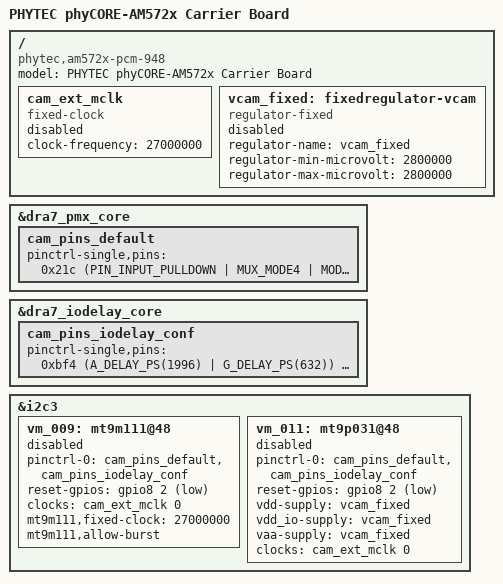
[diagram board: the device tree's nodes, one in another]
/*
 * Copyright (C) 2015 PHYTEC America, LLC - www.phytec.com
 *
 * This program is free software; you can redistribute it and/or modify
 * it under the terms of the GNU General Public License version 2 as
 * published by the Free Software Foundation.
 */

#include "am57xx-pcm-948-common.dtsi"

/ {
	model = "PHYTEC phyCORE-AM572x Carrier Board";
	compatible = "phytec,am572x-pcm-948", "phytec,am572x-phycore-som", "ti,am5728", "ti,dra742", "ti,dra74", "ti,dra7";

	/* For parallel camera interface at connector X23 */
	cam_ext_mclk: cam_ext_mclk {
		compatible = "fixed-clock";
		status = "disabled";

		#clock-cells = <0>;
		clock-frequency = <27000000>;
	};

	vcam_fixed: fixedregulator-vcam {
		compatible = "regulator-fixed";
		status = "disabled";

		regulator-name = "vcam_fixed";
		regulator-min-microvolt = <2800000>;
		regulator-max-microvolt = <2800000>;
	};
};

&dra7_pmx_core {
        cam_pins_default: cam_pins_default {
                pinctrl-single,pins = <
			0x21c (PIN_INPUT_PULLDOWN | MUX_MODE4 | MODE_SELECT)   /* vout1_d16.vin3a_d0 */
			0x220 (PIN_INPUT_PULLDOWN | MUX_MODE4 | MODE_SELECT)   /* vout1_d17.vin3a_d1 */
			0x224 (PIN_INPUT_PULLDOWN | MUX_MODE4 | MODE_SELECT)   /* vout1_d18.vin3a_d2 */
			0x228 (PIN_INPUT_PULLDOWN | MUX_MODE4 | MODE_SELECT)   /* vout1_d19.vin3a_d3 */
			0x144 (PIN_INPUT_PULLDOWN | MUX_MODE6 | MODE_SELECT)   /* vin1a_d20.vin3a_d4 */
			0x148 (PIN_INPUT_PULLDOWN | MUX_MODE6 | MODE_SELECT)   /* vin1a_d21.vin3a_d5 */
			0x14c (PIN_INPUT_PULLDOWN | MUX_MODE6 | MODE_SELECT)   /* vin1a_d22.vin3a_d6 */
			0x150 (PIN_INPUT_PULLDOWN | MUX_MODE6 | MODE_SELECT)   /* vin1a_d23.vin3a_d7 */

			0xe0 (PIN_INPUT | MUX_MODE6 | MODE_SELECT) /* vin1b_clk1.vin3a_clk0 */

			0x60 (PIN_INPUT_PULLDOWN | MUX_MODE2 | MODE_SELECT)   /* gpmc_a8.vin3a_hsync0 */
			0x64 (PIN_INPUT_PULLDOWN | MUX_MODE2 | MODE_SELECT)   /* gpmc_a9.vin3a_vsync0 */
			0x68 (PIN_INPUT_PULLDOWN | MUX_MODE2 | MODE_SELECT)   /* gpmc_a10.vin3a_de0 */
			0x6c (PIN_INPUT_PULLDOWN | MUX_MODE2 | MODE_SELECT)   /* gpmc_a11.vin3a_fld0 */

			0xc0 (PIN_OUTPUT | MUX_MODE2)	/* gpmc_clk.clkout1 */
			0x1e4 (PIN_OUTPUT | MUX_MODE14)   /* vout1_d2.gpio8_2 */
		>;
	};
};

&dra7_iodelay_core {
	cam_pins_iodelay_conf: cam_pins_iodelay_conf {
		pinctrl-single,pins = <
			0xbf4 (A_DELAY_PS(1996) | G_DELAY_PS(632))	/* CFG_VOUT1_D16_IN */
			0xc00 (A_DELAY_PS(2190) | G_DELAY_PS(790))	/* CFG_VOUT1_D17_IN */
			0xc0c (A_DELAY_PS(2100) | G_DELAY_PS(604))	/* CFG_VOUT1_D18_IN */
			0xc18 (A_DELAY_PS(2108) | G_DELAY_PS(286))	/* CFG_VOUT1_D19_IN */

			0x96c (A_DELAY_PS(1854) | G_DELAY_PS(1624))	/* CFG_VIN1A_D20_IN */
			0x978 (A_DELAY_PS(1906) | G_DELAY_PS(1520))	/* CFG_VIN1A_D21_IN */
			0x984 (A_DELAY_PS(1807) | G_DELAY_PS(1437))	/* CFG_VIN1A_D22_IN */
			0x990 (A_DELAY_PS(1996) | G_DELAY_PS(997))	/* CFG_VIN1A_D23_IN */

			0xa2c (A_DELAY_PS(0) | G_DELAY_PS(0))	/* CFG_VIN1B_CLK1_IN */

			0x24c (A_DELAY_PS(2154) | G_DELAY_PS(978))	/* CFG_GPMC_A8_IN */
			0x258 (A_DELAY_PS(2185) | G_DELAY_PS(1152))	/* CFG_GPMC_A9_IN */
			0x120 (A_DELAY_PS(2108) | G_DELAY_PS(823))	/* CFG_GPMC_A10_IN */
			0x12c (A_DELAY_PS(2068) | G_DELAY_PS(977))	/* CFG_GPMC_A11_IN */
		>;
	};
};

&i2c3 {
	vm_009: mt9m111@48 {
		status = "disabled";

		pinctrl-names = "default";
		pinctrl-0 = <&cam_pins_default &cam_pins_iodelay_conf>;
		reset-gpios = <&gpio8 2 1>;

		clocks = <&cam_ext_mclk 0>;
		clock-names = "mclk";

		mt9m111,fixed-clock = <27000000>;
		mt9m111,allow-burst;
	};

	vm_011: mt9p031@48 {
		status = "disabled";

		pinctrl-names = "default";
		pinctrl-0 = <&cam_pins_default &cam_pins_iodelay_conf>;
		reset-gpios = <&gpio8 2 1>;

		vdd-supply = <&vcam_fixed>;
		vdd_io-supply = <&vcam_fixed>;
		vaa-supply = <&vcam_fixed>;

		clocks = <&cam_ext_mclk 0>;
		clock-names = "mclk";
	};
};
